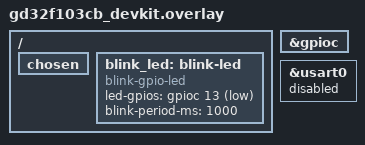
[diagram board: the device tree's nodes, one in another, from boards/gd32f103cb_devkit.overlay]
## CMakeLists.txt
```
#-------------------------------------------------------------------------------
# Zephyr Example Application
#
# Copyright (c) 2021 Nordic Semiconductor ASA
# SPDX-License-Identifier: Apache-2.0

cmake_minimum_required(VERSION 3.13.1)
find_package(Zephyr REQUIRED HINTS $ENV{ZEPHYR_BASE})

project(app LANGUAGES C)

target_sources(app PRIVATE src/main.c src/display.c)

# The code below locates the git index file for this repository and adds it as a dependency for
# the application VERSION file so that if the repo has a new commit added, even if no files in
# the build have changed, the application version file will be regenerated with the new git commit
find_package(Git QUIET)
if(GIT_FOUND)
  execute_process(
    COMMAND ${GIT_EXECUTABLE} rev-parse --absolute-git-dir
    WORKING_DIRECTORY .
    OUTPUT_VARIABLE application_git_dir
    OUTPUT_STRIP_TRAILING_WHITESPACE
    ERROR_STRIP_TRAILING_WHITESPACE
    ERROR_VARIABLE stderr
    RESULT_VARIABLE return_code
  )
  # If there is an error e.g. it is not a git repo, we just silently ignore it and continue
  # without a dependency, this will be the case with freestanding applications.
  if(NOT return_code)
    if(NOT "${stderr}" STREQUAL "")
      message(WARNING "Application build version git rev-parse warned: ${stderr}")
    endif()

    set_property(TARGET app_version_h PROPERTY APP_VERSION_DEPENDS ${application_git_dir}/index)
  endif()
endif()
```

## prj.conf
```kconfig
# Copyright (c) 2021 Nordic Semiconductor ASA
# SPDX-License-Identifier: Apache-2.0
#
# This file contains selected Kconfig options for the application.

CONFIG_BLINK=y
CONFIG_ISR_STACK_SIZE=1024
```

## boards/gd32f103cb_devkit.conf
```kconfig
# Copyright (c) 2021 Nordic Semiconductor ASA
# SPDX-License-Identifier: Apache-2.0
#
# Auto-merged with prj.conf when BOARD=gd32f103cb_devkit (see Zephyr
# APPLICATION_CONFIG_DIR/boards/<board>.conf).

# Console / printk -> SEGGER J-Link RTT (board overlay disables USART console).
CONFIG_CONSOLE=y
CONFIG_UART_CONSOLE=n
CONFIG_USE_SEGGER_RTT=y
CONFIG_RTT_CONSOLE=y

CONFIG_LOG=n
```

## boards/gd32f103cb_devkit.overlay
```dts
/*
 * Copyright (c) 2021 Nordic Semiconductor ASA
 * SPDX-License-Identifier: Apache-2.0
 *
 * GD32F103CB devkit: example blink + no USART console (use SEGGER RTT for printk).
 *
 * Kconfig for RTT is in boards/gd32f103cb_devkit.conf (merged automatically for
 * this board). Upstream board sets zephyr,console / zephyr,shell-uart to &usart0;
 * this overlay removes that binding and disables USART0.
 */

/ {
	chosen {
		/delete-property/ zephyr,console;
		/delete-property/ zephyr,shell-uart;
	};

	blink_led: blink-led {
		compatible = "blink-gpio-led";
		led-gpios = <&gpioc 13 GPIO_ACTIVE_LOW>;
		blink-period-ms = <1000>;
	};
};

&gpioc {
	status = "okay";
};

&usart0 {
	status = "disabled";
};
```

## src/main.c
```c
/*
 * Copyright (c) 2021 Nordic Semiconductor ASA
 * SPDX-License-Identifier: Apache-2.0
 */

#include <zephyr/kernel.h>
#include <zephyr/drivers/sensor.h>
#include <zephyr/logging/log.h>
#include <stdlib.h>

#include <app/display.h>
#include <app/drivers/blink.h>

#include <app_version.h>

LOG_MODULE_REGISTER(main, CONFIG_APP_LOG_LEVEL);

#define BLINK_PERIOD_MS_STEP 100U
#define BLINK_PERIOD_MS_MAX  1000U

int main(void)
{
	int ret;
	const struct device *blink;

	printk("Zephyr Example Application %s\n", APP_VERSION_STRING);

	display_thread_start();

	blink = DEVICE_DT_GET(DT_NODELABEL(blink_led));
	if (!device_is_ready(blink)) {
		LOG_ERR("Blink LED not ready");
		return 0;
	}

	ret = blink_off(blink);
	if (ret < 0) {
		LOG_ERR("Could not turn off LED (%d)", ret);
		return 0;
	}

	printk("Use the sensor to change LED blinking period\n");

	while (1) {
		uint32_t period_ms = (uint32_t)(rand() % BLINK_PERIOD_MS_MAX);
		struct display_msg dmsg = {
			.kind = DISPLAY_MSG_POWER,
			.arg = period_ms,
		};

		blink_set_period_ms(blink, (int)period_ms);

		if (display_post(&dmsg, K_NO_WAIT) != 0) {
			printk("main: display queue full, drop update\n");
		}

		k_sleep(K_MSEC(1000));
	}

	return 0;
}
```

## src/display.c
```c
/*
 * Copyright (c) 2021 Nordic Semiconductor ASA
 * SPDX-License-Identifier: Apache-2.0
 *
 * Display worker: lowest preemptible application priority (still above idle).
 * Communicates with main via k_msgq.
 */

#include <zephyr/kernel.h>
#include <zephyr/sys/atomic.h>

#include <app/display.h>

#define DISPLAY_STACK_SIZE 512U

K_THREAD_STACK_DEFINE(display_stack, DISPLAY_STACK_SIZE);

K_MSGQ_DEFINE(display_msgq, sizeof(struct display_msg), DISPLAY_MSGQ_MAX_MSGS, 4);

static struct k_thread display_thread_data;
static atomic_t display_started;

int display_post(const struct display_msg *msg, k_timeout_t timeout)
{
	return k_msgq_put(&display_msgq, msg, timeout);
}

static int display_power(int power)
{
	return 1000;
}

static void display_thread(void *p1, void *p2, void *p3)
{
	struct display_msg msg;

	ARG_UNUSED(p1);
	ARG_UNUSED(p2);
	ARG_UNUSED(p3);

    int delay = 0;
	for (;;) {
		/* Wait for work; periodic timeout allows future "idle refresh" if needed */
		if (k_msgq_get(&display_msgq, &msg, K_MSEC(delay)) != 0) {
			continue;
		}

		switch (msg.kind) {
		case DISPLAY_MSG_POWER:
			printk("display: power %d\n", msg.arg);
            delay = display_power(msg.arg);
			break;
		case DISPLAY_MSG_NORMAL:
			printk("display: normal\n");
			break;
		case DISPLAY_MSG_BREAK:
			printk("display: break\n");
			break;
		case DISPLAY_MSG_TURN:
			printk("display: turn\n");
			break;
		default:
			printk("display: unknown kind %u\n", msg.kind);
			break;
		}
	}
}

void display_thread_start(void)
{
	if (!atomic_cas(&display_started, 0, 1)) {
		return;
	}

	k_thread_create(&display_thread_data, display_stack,
			K_THREAD_STACK_SIZEOF(display_stack), display_thread, NULL, NULL, NULL,
			K_LOWEST_APPLICATION_THREAD_PRIO, 0, K_NO_WAIT);
	k_thread_name_set(&display_thread_data, "display");
}
```
